# PIC16LF1779 register map
Vendor: Microchip
Registers are 8-bit, read-write, reset 0x0 unless marked. A register's access mark holds for its fields unless they carry their own. Addresses are absolute, and some are shared; only a register's first bit layout is shown; [hi:lo] are bit positions; {n}, {i} and the like mark numbered series.

## mssp
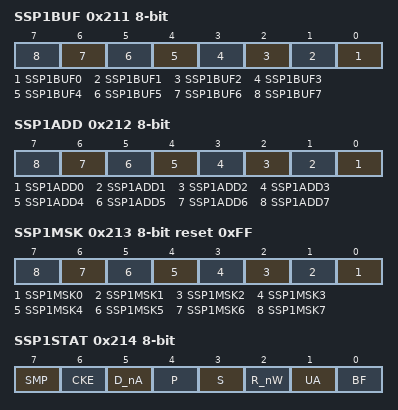
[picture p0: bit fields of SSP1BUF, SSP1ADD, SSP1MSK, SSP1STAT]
0x211 SSP1BUF reset not defined — (power-on value xxxxxxxx)
  [n] SSP1BUF{n} (n=0..7)
0x212 SSP1ADD
  [n] SSP1ADD{n} (n=0..7)
0x213 SSP1MSK reset 0xFF
  [n] SSP1MSK{n} (n=0..7)
0x214 SSP1STAT
  [7] SMP, [6] CKE, [5] D_nA ro, [4] P ro, [3] S ro, [2] R_nW ro, [1] UA ro, [0] BF ro
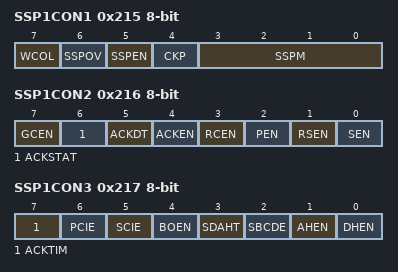
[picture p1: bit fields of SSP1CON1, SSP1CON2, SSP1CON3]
0x215 SSP1CON1
  [7] WCOL, [6] SSPOV, [5] SSPEN, [4] CKP, [3:0] SSPM
0x216 SSP1CON2
  [7] GCEN, [6] ACKSTAT ro, [5] ACKDT, [4] ACKEN, [3] RCEN, [2] PEN, [1] RSEN, [0] SEN
0x217 SSP1CON3
  [7] ACKTIM ro, [6] PCIE, [5] SCIE, [4] BOEN, [3] SDAHT, [2] SBCDE, [1] AHEN, [0] DHEN

## txm_mod
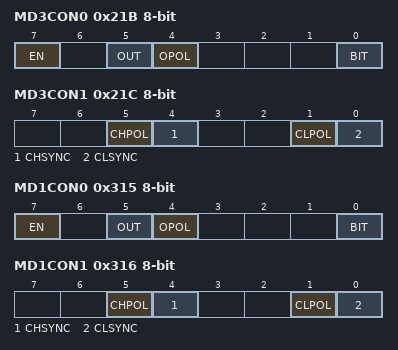
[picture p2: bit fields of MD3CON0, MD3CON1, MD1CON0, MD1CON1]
0x21B MD3CON0
  [7] EN, [5] OUT ro, [4] OPOL, [0] BIT
0x21C MD3CON1
  [5] CHPOL, [4] CHSYNC, [1] CLPOL, [0] CLSYNC
0x21D MD3SRC
  [4:0] MS
0x21E MD3CARL reset not defined — (power-on value ---x0000)
  [4:0] CL
0x21F MD3CARH reset not defined — (power-on value ---x0000)
  [4:0] CH
0x315 MD1CON0
  [7] EN, [5] OUT ro, [4] OPOL, [0] BIT
0x316 MD1CON1
  [5] CHPOL, [4] CHSYNC, [1] CLPOL, [0] CLSYNC
0x317 MD1SRC
  [4:0] MS
0x318 MD1CARL reset not defined — (power-on value ---x0000)
  [4:0] CL
0x319 MD1CARH reset not defined — (power-on value ---x0000)
  [4:0] CH
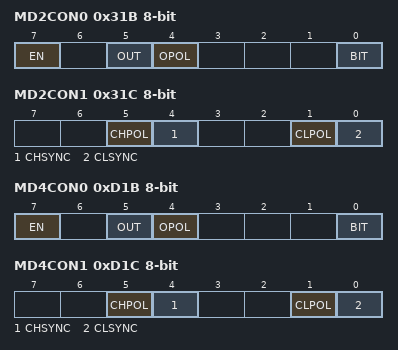
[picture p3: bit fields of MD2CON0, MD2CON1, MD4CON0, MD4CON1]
0x31B MD2CON0
  [7] EN, [5] OUT ro, [4] OPOL, [0] BIT
0x31C MD2CON1
  [5] CHPOL, [4] CHSYNC, [1] CLPOL, [0] CLSYNC
0x31D MD2SRC
  [4:0] MS
0x31E MD2CARL reset not defined — (power-on value ---x0000)
  [4:0] CL
0x31F MD2CARH reset not defined — (power-on value ---x0000)
  [4:0] CH
0xD1B MD4CON0
  [7] EN, [5] OUT ro, [4] OPOL, [0] BIT
0xD1C MD4CON1
  [5] CHPOL, [4] CHSYNC, [1] CLPOL, [0] CLSYNC
0xD1D MD4SRC
  [4:0] MS
0xD1E MD4CARL reset not defined — (power-on value ---x0000)
  [4:0] CL
0xD1F MD4CARH reset not defined — (power-on value ---x0000)
  [4:0] CH

## ccp
0x291 CCPR1L reset not defined — (power-on value xxxxxxxx)
  [7:0] RL
0x292 CCPR1H reset not defined — (power-on value xxxxxxxx)
  [7:0] RH
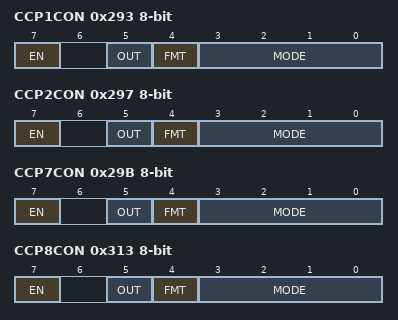
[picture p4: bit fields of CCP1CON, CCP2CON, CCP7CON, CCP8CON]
0x293 CCP1CON
  [7] EN, [5] OUT ro, [4] FMT, [3:0] MODE
0x294 CCP1CAP
  [3:0] CTS
0x295 CCPR2L reset not defined — (power-on value xxxxxxxx)
  [7:0] RL
0x296 CCPR2H reset not defined — (power-on value xxxxxxxx)
  [7:0] RH
0x297 CCP2CON
  [7] EN, [5] OUT ro, [4] FMT, [3:0] MODE
0x298 CCP2CAP
  [3:0] CTS
0x299 CCPR7L reset not defined — (power-on value xxxxxxxx)
  [7:0] RL
0x29A CCPR7H reset not defined — (power-on value xxxxxxxx)
  [7:0] RH
0x29B CCP7CON
  [7] EN, [5] OUT ro, [4] FMT, [3:0] MODE
0x29C CCP7CAP
  [3:0] CTS
0x311 CCPR8L reset not defined — (power-on value xxxxxxxx)
  [7:0] RL
0x312 CCPR8H reset not defined — (power-on value xxxxxxxx)
  [7:0] RH
0x313 CCP8CON
  [7] EN, [5] OUT ro, [4] FMT, [3:0] MODE
0x314 CCP8CAP
  [3:0] CTS

## tmr
0x413 T4TMR — 8-bit period timer
  [7:0] TMR
0x414 T4PR reset 0xFF
  [7:0] PR
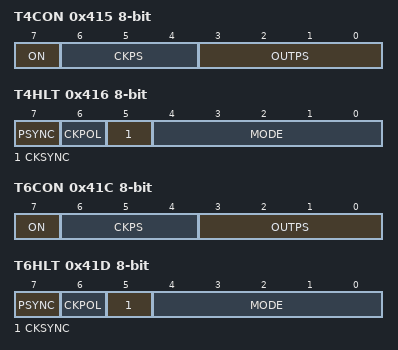
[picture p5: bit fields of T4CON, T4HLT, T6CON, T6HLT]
0x415 T4CON
  [7] ON, [6:4] CKPS, [3:0] OUTPS
0x416 T4HLT
  [7] PSYNC, [6] CKPOL, [5] CKSYNC, [4:0] MODE
0x417 T4CLKCON
  [3:0] CS
0x418 T4RST reset not defined — (power-on value ---x0000)
  [4:0] RSEL
0x41A T6TMR — 8-bit period timer
  [7:0] TMR
0x41B T6PR reset 0xFF
  [7:0] PR
0x41C T6CON
  [7] ON, [6:4] CKPS, [3:0] OUTPS
0x41D T6HLT
  [7] PSYNC, [6] CKPOL, [5] CKSYNC, [4:0] MODE
0x41E T6CLKCON
  [3:0] CS
0x41F T6RST reset not defined — (power-on value ---x0000)
  [4:0] RSEL
0x493 T2TMR — 8-bit period timer
  [7:0] TMR
0x494 T2PR reset 0xFF
  [7:0] PR
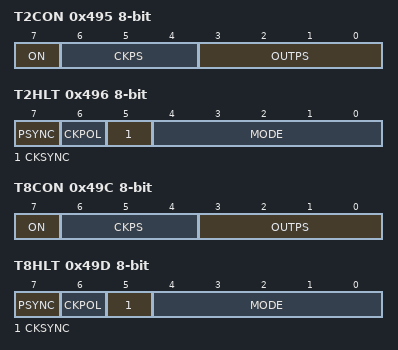
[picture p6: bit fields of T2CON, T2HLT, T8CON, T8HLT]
0x495 T2CON
  [7] ON, [6:4] CKPS, [3:0] OUTPS
0x496 T2HLT
  [7] PSYNC, [6] CKPOL, [5] CKSYNC, [4:0] MODE
0x497 T2CLKCON
  [3:0] CS
0x498 T2RST reset not defined — (power-on value ---x0000)
  [4:0] RSEL
0x49A T8TMR — 8-bit period timer
  [7:0] TMR
0x49B T8PR reset 0xFF
  [7:0] PR
0x49C T8CON
  [7] ON, [6:4] CKPS, [3:0] OUTPS
0x49D T8HLT
  [7] PSYNC, [6] CKPOL, [5] CKSYNC, [4:0] MODE
0x49E T8CLKCON
  [3:0] CS
0x49F T8RST reset not defined — (power-on value ---x0000)
  [4:0] RSEL
